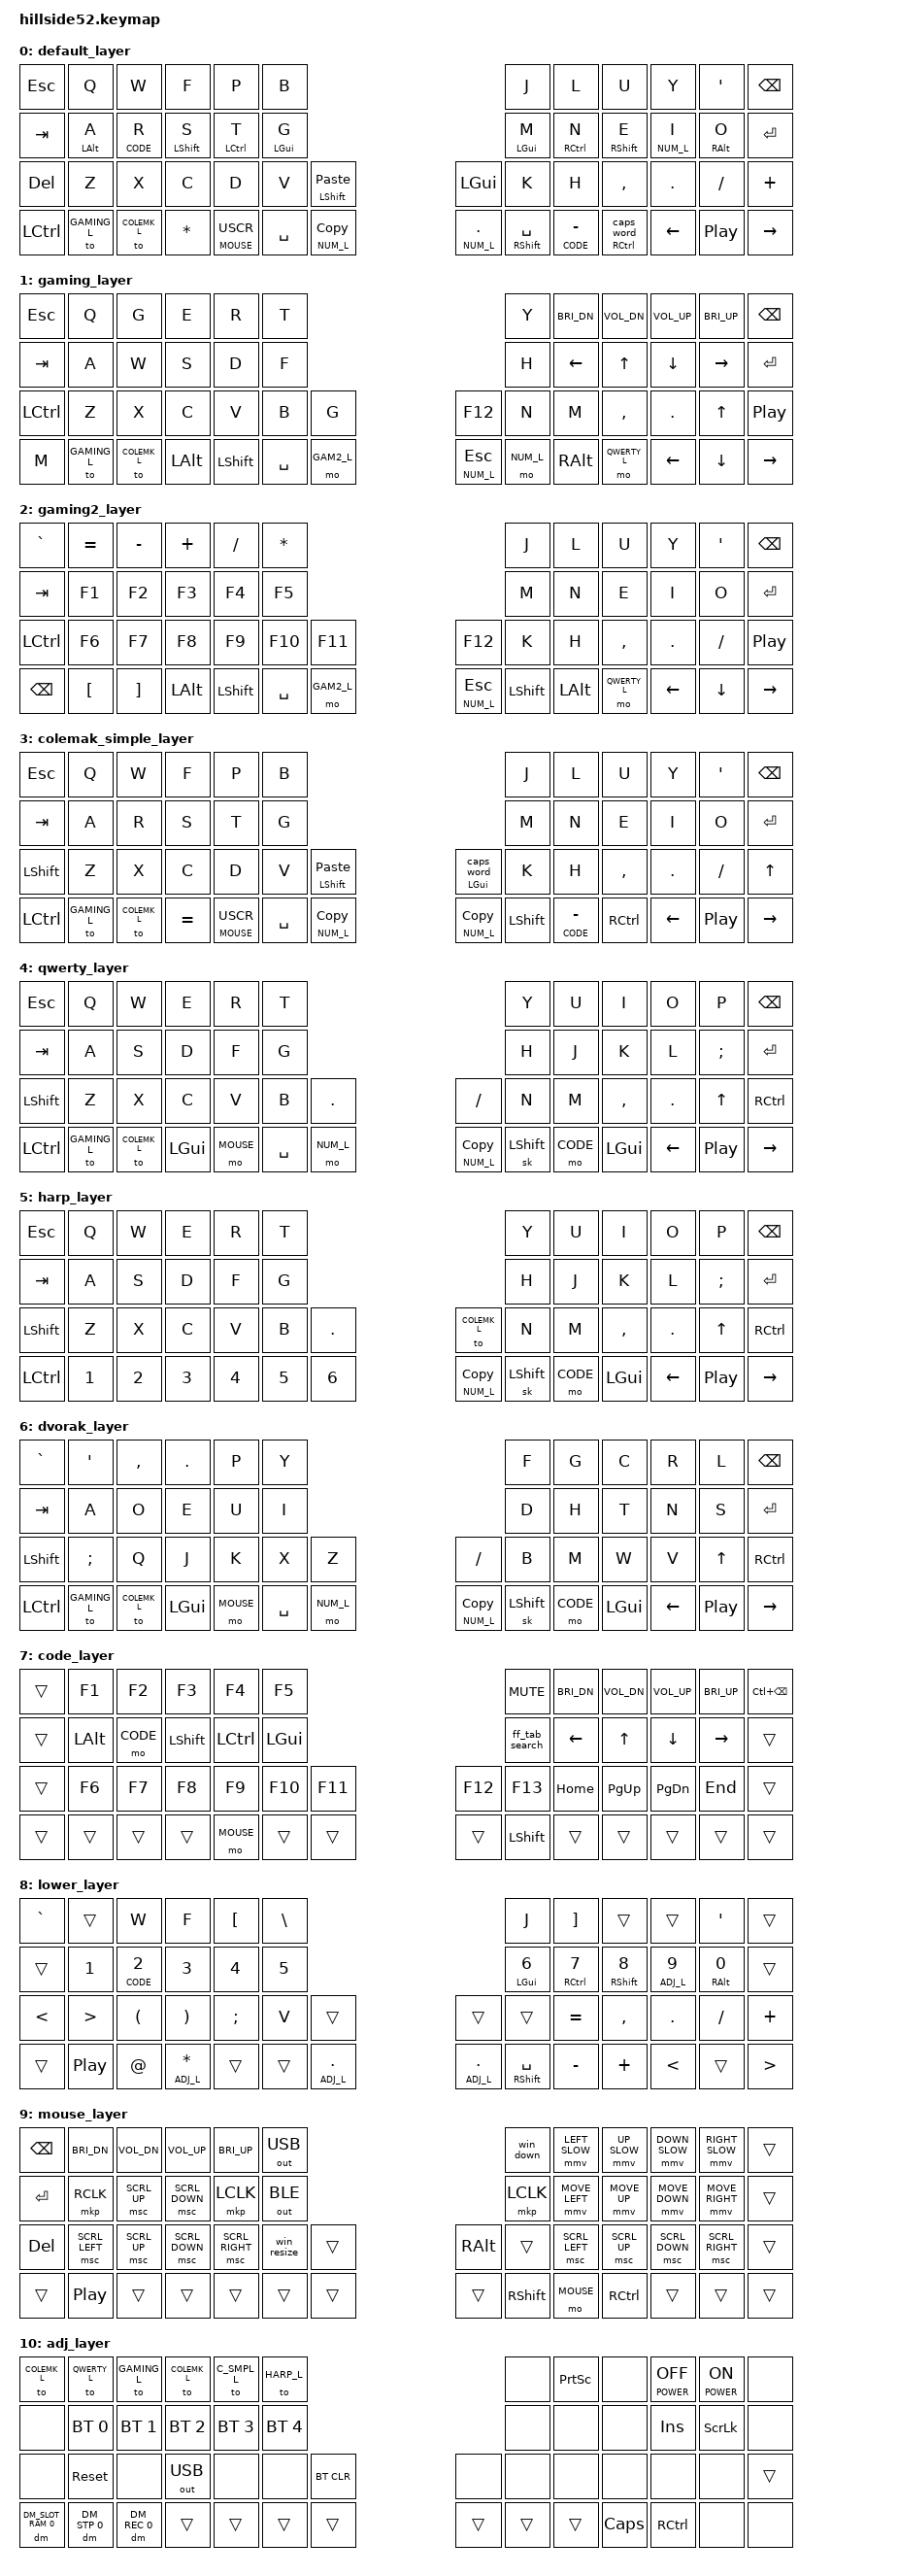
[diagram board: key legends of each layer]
/*
 * Copyright (c) 2021-2022 The ZMK Contributors
 *
 * SPDX-License-Identifier: MIT
 */

#include <behaviors.dtsi>
#include <dt-bindings/zmk/bt.h>
#include <dt-bindings/zmk/ext_power.h>
#include <dt-bindings/zmk/keys.h>
#include <dt-bindings/zmk/outputs.h>

#include <dt-bindings/zmk/mouse.h>
#include <behaviors/mouse_keys.dtsi>

#include <dt-bindings/zmk/kscan_mock.h>

#include <dt-bindings/zmk/dynamic_macros.h>
#include <behaviors/dynamic_macro.dtsi>

#define USCR UNDERSCORE
#define POWER ext_power
 
#define COLEMK_L 0
#define GAMING_L 1
#define GAM2_L   2
#define C_SMPL_L 3
#define QWERTY_L 4
#define HARP_L   5
#define DVORAK_L 6
#define CODE     7
#define NUM_L    8
#define MOUSE    9
#define ADJ_L    10

#define Undo   LC(Z)
#define Cut    LC(X)
#define Copy   LC(C)
#define Paste  LC(V)
#define Redo   LC(Y)

#define U_MOUSE_MOVE_MAX 1600                     /* <--- New max speed setting (default: 600) */
#undef MOVE_UP
#undef MOVE_DOWN
#undef MOVE_LEFT
#undef MOVE_RIGHT
#define MOVE_UP MOVE_Y(-U_MOUSE_MOVE_MAX)
#define MOVE_DOWN MOVE_Y(U_MOUSE_MOVE_MAX)
#define MOVE_LEFT MOVE_X(-U_MOUSE_MOVE_MAX)
#define MOVE_RIGHT MOVE_X(U_MOUSE_MOVE_MAX)


#define U_MOUSE_MOVE_SLOW_MAX 500                     /* <--- New max speed setting (default: 600) */
#define UP_SLOW MOVE_Y(-U_MOUSE_MOVE_SLOW_MAX)
#define DOWN_SLOW MOVE_Y(U_MOUSE_MOVE_SLOW_MAX)
#define LEFT_SLOW MOVE_X(-U_MOUSE_MOVE_SLOW_MAX)
#define RIGHT_SLOW MOVE_X(U_MOUSE_MOVE_SLOW_MAX)

#define U_MOUSE_SCRL_MAX 15                    /* <--- New max speed setting (default: 10) */
#undef SCRL_UP
#undef SCRL_DOWN
#undef SCRL_LEFT
#undef SCRL_RIGHT
#define SCRL_UP MOVE_Y(U_MOUSE_SCRL_MAX)
#define SCRL_DOWN MOVE_Y(-U_MOUSE_SCRL_MAX)
#define SCRL_LEFT MOVE_X(-U_MOUSE_SCRL_MAX)
#define SCRL_RIGHT MOVE_X(U_MOUSE_SCRL_MAX)

&msc {
  time-to-max-speed-ms = <1>;                 /* <--- How long time until max speed is reached (default: 300) */
};

&caps_word {
        continue-list = <USCR MINUS BSPC LS(BSPC)>;
};
&mmv {
	time-to-max-speed-ms = <300>;             /* <--- How long time until max speed is reached (default: 300) */
};

/ {
	macros {
		ff_tab_search: ff_tab_search {
		    compatible = "zmk,behavior-macro";
		    #binding-cells = <0>;
		    bindings
			= <&macro_press &kp LCTRL>
			, <&macro_tap &kp T>
			, <&macro_release &kp LCTRL>
			, <&macro_tap &kp PERCENT &kp SPACE>
			;
		};
		win_up: win_up {
		    compatible = "zmk,behavior-macro";
		    #binding-cells = <0>;
		    bindings
			= <&macro_press &kp LGUI>
			, <&macro_tap &kp UP>
			, <&macro_release &kp LGUI>
			;
		};
		win_down: win_down {
		    compatible = "zmk,behavior-macro";
		    #binding-cells = <0>;
		    bindings
			= <&macro_press &kp LGUI>
			, <&macro_tap &kp DOWN>
			, <&macro_release &kp LGUI>
			;
		};
		win_resize: win_resize {
		    compatible = "zmk,behavior-macro";
		    #binding-cells = <0>;
		    bindings
			= <&macro_tap &mkp RCLK>
			, <&macro_tap &kp ESC>

			, <&macro_press &kp LALT>
			, <&macro_tap &kp SPACE>
			, <&macro_release &kp LALT>
			, <&macro_tap &kp S &kp UP &kp LEFT>

    			, <&macro_pause_for_release>
			, <&macro_tap &mkp LCLK>
			;
		};
		win_move: win_move {
		    compatible = "zmk,behavior-macro";
		    #binding-cells = <0>;
		    bindings
			= <&macro_tap &mkp RCLK>
			, <&macro_tap &kp ESC>

			, <&macro_press &kp LALT>
			, <&macro_tap &kp SPACE>
			, <&macro_release &kp LALT>
			, <&macro_tap &kp M &kp DOWN>

			, <&macro_pause_for_release>
			, <&macro_tap &mkp LCLK>
			;
		};
	};
        behaviors {
        hlf: homerow_layer_fast {
            compatible = "zmk,behavior-hold-tap";
            #binding-cells = <2>;
            tapping-term-ms = <190>;
            require-prior-idle-ms = <0>;
            quick-tap-ms = <0>;
            flavor = "balanced";
            bindings = <&mo>, <&kp>;
            };
        hl: homerow_layer {
            compatible = "zmk,behavior-hold-tap";
            #binding-cells = <2>;
            tapping-term-ms = <400>;
            require-prior-idle-ms = <0>;
            quick-tap-ms = <0>;
            flavor = "balanced";
            bindings = <&mo>, <&kp>;
            };
        hm: homerow_mods {
            compatible = "zmk,behavior-hold-tap";
            #binding-cells = <2>;
            tapping-term-ms = <400>;
            require-prior-idle-ms = <0>;
            quick-tap-ms = <0>;
            flavor = "balanced";
            bindings = <&kp>, <&kp>;
            };
        mpcaps: mod_preferred_caps_word {
            compatible = "zmk,behavior-hold-tap";
            #binding-cells = <2>;
            tapping-term-ms = <300>;
            quick-tap-ms = <0>;
            flavor = "hold-preferred";
            bindings = <&kp>, <&caps_word>;
            };
        mp: mod_preferred {
            compatible = "zmk,behavior-hold-tap";
            #binding-cells = <2>;
            tapping-term-ms = <300>;
            quick-tap-ms = <0>;
            flavor = "hold-preferred";
            bindings = <&kp>, <&kp>;
            };
        mlt: my_layer_tap {
            compatible = "zmk,behavior-hold-tap";
            #binding-cells = <2>;
            tapping-term-ms = <300>;
            quick-tap-ms = <0>;
            flavor = "hold-preferred";
            bindings = <&mo>, <&kp>;
            };
        };

        keymap {
                compatible = "zmk,keymap";

                default_layer {
/* COLEMAK-DH
 */
                        bindings = <
//──────────────┬───────────────┬───────────────┬───────────────┬───────────────┬───────────────┐                                                               ┌───────────────┬───────────────┬───────────────┬───────────────┬───────────────┬───────────────┐
&kp ESC         &kp Q           &kp W           &kp F           &kp P           &kp B                                                                           &kp J           &kp L           &kp U           &kp Y           &kp SQT         &kp BSPC
//──────────────┼───────────────┼───────────────┼───────────────┼───────────────┼───────────────┤                                                               ├───────────────┼───────────────┼───────────────┼───────────────┼───────────────┼───────────────┤
&kp TAB         &hm LALT A      &hl CODE R      &hm LSHIFT S    &hm LCTRL T     &hm LGUI G                                                                      &hm LGUI M      &hm RCTRL N     &hm RSHIFT E    &hlf NUM_L I    &hm RALT O      &kp ENTER
//──────────────┼───────────────┼───────────────┼───────────────┼───────────────┼───────────────┤                                                               ├───────────────┼───────────────┼───────────────┼───────────────┼───────────────┼───────────────┤
&kp DEL         &kp Z           &kp X           &kp C           &kp D           &kp V           &hm LSHIFT Paste                                &kp LGUI        &kp K           &kp H           &kp COMMA       &kp DOT         &kp SLASH       &kp PLUS
//──────────────┼───────────────┼───────────────┼───────────────┼───────────────┼───────────────┼───────────────┼───────────────┼───────────────┼───────────────┼───────────────┼───────────────┼───────────────┼───────────────┼───────────────┼───────────────┤
&kp LCTRL       &to GAMING_L    &to COLEMK_L                    &kp ASTRK       &mlt MOUSE USCR &kp SPACE       &hl NUM_L Copy  &hl NUM_L DOT   &mp RSHIFT SPACE&hl CODE MINUS  &mpcaps RCTRL 0                 &kp LEFT        &kp C_PLAY_PAUSE&kp RIGHT
//──────────────┴───────────────┴───────────────┴───────────────┴───────────────┴───────────────┴───────────────┴───────────────┴───────────────┴───────────────┴───────────────┴───────────────┴───────────────┴───────────────┴───────────────┴───────────────┘
    >;

                        sensor-bindings = <&inc_dec_kp C_VOL_UP C_VOL_DN &inc_dec_kp PG_UP PG_DN>;
                };

                gaming_layer {
/* GAMING_L
 */
                        bindings = <
//──────────────┬───────────────┬───────────────┬───────────────┬───────────────┬───────────────┐                                                               ┌───────────────┬───────────────┬───────────────┬───────────────┬───────────────┬───────────────┐
&kp ESC         &kp Q           &kp G           &kp E           &kp R           &kp T                                                                           &kp Y           &kp C_BRI_DN    &kp C_VOL_DN    &kp C_VOL_UP    &kp C_BRI_UP    &kp BSPC
//──────────────┼───────────────┼───────────────┼───────────────┼───────────────┼───────────────┤                                                               ├───────────────┼───────────────┼───────────────┼───────────────┼───────────────┼───────────────┤
&kp TAB         &kp A           &kp W           &kp S           &kp D           &kp F                                                                           &kp H           &kp LEFT        &kp UP          &kp DOWN        &kp RIGHT       &kp ENTER
//──────────────┼───────────────┼───────────────┼───────────────┼───────────────┼───────────────┤                                                               ├───────────────┼───────────────┼───────────────┼───────────────┼───────────────┼───────────────┤
&kp LCTRL       &kp Z           &kp X           &kp C           &kp V           &kp B           &kp G                                           &kp F12         &kp N           &kp M           &kp COMMA       &kp DOT         &kp UP          &kp C_PLAY_PAUSE
//──────────────┼───────────────┼───────────────┼───────────────┼───────────────┼───────────────┼───────────────┼───────────────┼───────────────┼───────────────┼───────────────┼───────────────┼───────────────┼───────────────┼───────────────┼───────────────┤
&kp M           &to GAMING_L    &to COLEMK_L                    &kp LALT        &kp LSHIFT      &kp SPACE       &mo GAM2_L      &hl NUM_L ESC   &mo NUM_L       &kp RALT        &mo QWERTY_L                    &kp LEFT        &kp DOWN        &kp RIGHT
//──────────────┴───────────────┴───────────────┴───────────────┴───────────────┴───────────────┴───────────────┴───────────────┴───────────────┴───────────────┴───────────────┴───────────────┴───────────────┴───────────────┴───────────────┴───────────────┘
    >;

                        sensor-bindings = <&inc_dec_kp C_VOL_UP C_VOL_DN &inc_dec_kp PG_UP PG_DN>;
                };
                gaming2_layer {
/* GAM2_L
 */
                        bindings = <
//──────────────┬───────────────┬───────────────┬───────────────┬───────────────┬───────────────┐                                                               ┌───────────────┬───────────────┬───────────────┬───────────────┬───────────────┬───────────────┐
&kp GRAVE       &kp EQUAL       &kp MINUS       &kp PLUS        &kp SLASH       &kp ASTRK                                                                       &kp J           &kp L           &kp U           &kp Y           &kp SQT         &kp BSPC
//──────────────┼───────────────┼───────────────┼───────────────┼───────────────┼───────────────┤                                                               ├───────────────┼───────────────┼───────────────┼───────────────┼───────────────┼───────────────┤
&kp TAB         &kp F1          &kp F2          &kp F3          &kp F4          &kp F5                                                                          &kp M           &kp N           &kp E           &kp I           &kp O           &kp ENTER
//──────────────┼───────────────┼───────────────┼───────────────┼───────────────┼───────────────┤                                                               ├───────────────┼───────────────┼───────────────┼───────────────┼───────────────┼───────────────┤
&kp LCTRL       &kp F6          &kp F7          &kp F8          &kp F9          &kp F10         &kp F11                                         &kp F12         &kp K           &kp H           &kp COMMA       &kp DOT         &kp SLASH       &kp C_PLAY_PAUSE
//──────────────┼───────────────┼───────────────┼───────────────┼───────────────┼───────────────┼───────────────┼───────────────┼───────────────┼───────────────┼───────────────┼───────────────┼───────────────┼───────────────┼───────────────┼───────────────┤
&kp BSPC        &kp LBKT        &kp RBKT                        &kp LALT        &kp LSHIFT      &kp SPACE       &mo GAM2_L      &hl NUM_L ESC   &kp LSHIFT      &kp LALT        &mo QWERTY_L                    &kp LEFT        &kp DOWN        &kp RIGHT
//──────────────┴───────────────┴───────────────┴───────────────┴───────────────┴───────────────┴───────────────┴───────────────┴───────────────┴───────────────┴───────────────┴───────────────┴───────────────┴───────────────┴───────────────┴───────────────┘
    >;

                        sensor-bindings = <&inc_dec_kp C_VOL_UP C_VOL_DN &inc_dec_kp PG_UP PG_DN>;
                };

                colemak_simple_layer {
/* C_SMPL_L (no home row mods an fewer multi-purpose keys. useful for some games)
 */
                        bindings = <
//──────────────┬───────────────┬───────────────┬───────────────┬───────────────┬───────────────┐                                                               ┌───────────────┬───────────────┬───────────────┬───────────────┬───────────────┬───────────────┐
&kp ESC         &kp Q           &kp W           &kp F           &kp P           &kp B                                                                           &kp J           &kp L           &kp U           &kp Y           &kp SQT         &kp BSPC
//──────────────┼───────────────┼───────────────┼───────────────┼───────────────┼───────────────┤                                                               ├───────────────┼───────────────┼───────────────┼───────────────┼───────────────┼───────────────┤
&kp TAB         &kp A           &kp R           &kp S           &kp T           &kp G                                                                           &kp M           &kp N           &kp E           &kp I           &kp O           &kp ENTER
//──────────────┼───────────────┼───────────────┼───────────────┼───────────────┼───────────────┤                                                               ├───────────────┼───────────────┼───────────────┼───────────────┼───────────────┼───────────────┤
&kp LSHFT       &kp Z           &kp X           &kp C           &kp D           &kp V           &hm LSHIFT Paste                                &mpcaps LGUI 0  &kp K           &kp H           &kp COMMA       &kp DOT         &kp SLASH       &kp UP
//──────────────┼───────────────┼───────────────┼───────────────┼───────────────┼───────────────┼───────────────┼───────────────┼───────────────┼───────────────┼───────────────┼───────────────┼───────────────┼───────────────┼───────────────┼───────────────┤
&kp LCTRL       &to GAMING_L    &to COLEMK_L                    &kp EQUAL       &mlt MOUSE USCR &kp SPACE       &hl NUM_L Copy  &hl NUM_L Copy  &kp LSHIFT      &hl CODE MINUS  &kp RCTRL                       &kp LEFT        &kp C_PLAY_PAUSE&kp RIGHT
//──────────────┴───────────────┴───────────────┴───────────────┴───────────────┴───────────────┴───────────────┴───────────────┴───────────────┴───────────────┴───────────────┴───────────────┴───────────────┴───────────────┴───────────────┴───────────────┘
    >;

                        sensor-bindings = <&inc_dec_kp C_VOL_UP C_VOL_DN &inc_dec_kp PG_UP PG_DN>;
                };

                qwerty_layer {
/* QWERTY
 */
                        bindings = <
//──────────────┬───────────────┬───────────────┬───────────────┬───────────────┬───────────────┐                                                               ┌───────────────┬───────────────┬───────────────┬───────────────┬───────────────┬───────────────┐
&kp ESC         &kp Q           &kp W           &kp E           &kp R           &kp T                                                                           &kp Y           &kp U           &kp I           &kp O           &kp P           &kp BSPC
//──────────────┼───────────────┼───────────────┼───────────────┼───────────────┼───────────────┤                                                               ├───────────────┼───────────────┼───────────────┼───────────────┼───────────────┼───────────────┤
&kp TAB         &kp A           &kp S           &kp D           &kp F           &kp G                                                                           &kp H           &kp J           &kp K           &kp L           &kp SEMI        &kp ENTER
//──────────────┼───────────────┼───────────────┼───────────────┼───────────────┼───────────────┤                                                               ├───────────────┼───────────────┼───────────────┼───────────────┼───────────────┼───────────────┤
&kp LSHFT       &kp Z           &kp X           &kp C           &kp V           &kp B           &kp DOT                                         &kp SLASH       &kp N           &kp M           &kp COMMA       &kp DOT         &kp UP          &kp RCTRL
//──────────────┼───────────────┼───────────────┼───────────────┼───────────────┼───────────────┼───────────────┼───────────────┼───────────────┼───────────────┼───────────────┼───────────────┼───────────────┼───────────────┼───────────────┼───────────────┤
&kp LCTRL       &to GAMING_L    &to COLEMK_L                    &kp LGUI        &mo MOUSE       &kp SPACE       &mo NUM_L       &lt NUM_L Copy  &sk LSHIFT      &mo CODE        &kp LGUI                        &kp LEFT        &kp C_PLAY_PAUSE&kp RIGHT
//──────────────┴───────────────┴───────────────┴───────────────┴───────────────┴───────────────┴───────────────┴───────────────┴───────────────┴───────────────┴───────────────┴───────────────┴───────────────┴───────────────┴───────────────┴───────────────┘
    >;

                        sensor-bindings = <&inc_dec_kp C_VOL_UP C_VOL_DN &inc_dec_kp PG_UP PG_DN>;
                };

                harp_layer {
/* HARP_L: RUST HARP INPUTS
 */
                        bindings = <
//──────────────┬───────────────┬───────────────┬───────────────┬───────────────┬───────────────┐                                                               ┌───────────────┬───────────────┬───────────────┬───────────────┬───────────────┬───────────────┐
&kp ESC         &kp Q           &kp W           &kp E           &kp R           &kp T                                                                           &kp Y           &kp U           &kp I           &kp O           &kp P           &kp BSPC
//──────────────┼───────────────┼───────────────┼───────────────┼───────────────┼───────────────┤                                                               ├───────────────┼───────────────┼───────────────┼───────────────┼───────────────┼───────────────┤
&kp TAB         &kp A           &kp S           &kp D           &kp F           &kp G                                                                           &kp H           &kp J           &kp K           &kp L           &kp SEMI        &kp ENTER
//──────────────┼───────────────┼───────────────┼───────────────┼───────────────┼───────────────┤                                                               ├───────────────┼───────────────┼───────────────┼───────────────┼───────────────┼───────────────┤
&kp LSHFT       &kp Z           &kp X           &kp C           &kp V           &kp B           &kp DOT                                         &to COLEMK_L    &kp N           &kp M           &kp COMMA       &kp DOT         &kp UP          &kp RCTRL
//──────────────┼───────────────┼───────────────┼───────────────┼───────────────┼───────────────┼───────────────┼───────────────┼───────────────┼───────────────┼───────────────┼───────────────┼───────────────┼───────────────┼───────────────┼───────────────┤
&kp LCTRL       &kp N1          &kp N2                          &kp N3          &kp N4          &kp N5          &kp N6          &lt NUM_L Copy  &sk LSHIFT      &mo CODE        &kp LGUI                        &kp LEFT        &kp C_PLAY_PAUSE&kp RIGHT
//──────────────┴───────────────┴───────────────┴───────────────┴───────────────┴───────────────┴───────────────┴───────────────┴───────────────┴───────────────┴───────────────┴───────────────┴───────────────┴───────────────┴───────────────┴───────────────┘
    >;

                        sensor-bindings = <&inc_dec_kp C_VOL_UP C_VOL_DN &inc_dec_kp PG_UP PG_DN>;
                };

                dvorak_layer {
/* DVORAK
 */
                        bindings = <
//──────────────┬───────────────┬───────────────┬───────────────┬───────────────┬───────────────┐                                                               ┌───────────────┬───────────────┬───────────────┬───────────────┬───────────────┬───────────────┐
&kp GRAVE       &kp SQT         &kp COMMA       &kp DOT         &kp P           &kp Y                                                                           &kp F           &kp G           &kp C           &kp R           &kp L           &kp BSPC
//──────────────┼───────────────┼───────────────┼───────────────┼───────────────┼───────────────┤                                                               ├───────────────┼───────────────┼───────────────┼───────────────┼───────────────┼───────────────┤
&kp TAB         &kp A           &kp O           &kp E           &kp U           &kp I                                                                           &kp D           &kp H           &kp T           &kp N           &kp S           &kp ENTER
//──────────────┼───────────────┼───────────────┼───────────────┼───────────────┼───────────────┤                                                               ├───────────────┼───────────────┼───────────────┼───────────────┼───────────────┼───────────────┤
&kp LSHFT       &kp SEMI        &kp Q           &kp J           &kp K           &kp X           &kp Z                                           &kp SLASH       &kp B           &kp M           &kp W           &kp V           &kp UP          &kp RCTRL
//──────────────┼───────────────┼───────────────┼───────────────┼───────────────┼───────────────┼───────────────┼───────────────┼───────────────┼───────────────┼───────────────┼───────────────┼───────────────┼───────────────┼───────────────┼───────────────┤
&kp LCTRL       &to GAMING_L    &to COLEMK_L                    &kp LGUI        &mo MOUSE       &kp SPACE       &mo NUM_L       &lt NUM_L Copy  &sk LSHIFT      &mo CODE        &kp LGUI                        &kp LEFT        &kp C_PLAY_PAUSE&kp RIGHT
//──────────────┴───────────────┴───────────────┴───────────────┴───────────────┴───────────────┴───────────────┴───────────────┴───────────────┴───────────────┴───────────────┴───────────────┴───────────────┴───────────────┴───────────────┴───────────────┘
    >;

                        sensor-bindings = <&inc_dec_kp C_VOL_UP C_VOL_DN &inc_dec_kp PG_UP PG_DN>;
                };

                code_layer {
/* CODE
 */
                        bindings = <
//──────────────┬───────────────┬───────────────┬───────────────┬───────────────┬───────────────┐                                                               ┌───────────────┬───────────────┬───────────────┬───────────────┬───────────────┬───────────────┐
&trans          &kp F1          &kp F2          &kp F3          &kp F4          &kp F5                                                                          &kp C_MUTE      &kp C_BRI_DN    &kp C_VOL_DN    &kp C_VOL_UP    &kp C_BRI_UP    &kp LC(BSPC)
//──────────────┼───────────────┼───────────────┼───────────────┼───────────────┼───────────────┤                                                               ├───────────────┼───────────────┼───────────────┼───────────────┼───────────────┼───────────────┤
&trans          &kp LALT        &mo CODE        &kp LSHIFT      &kp LCTRL       &kp LGUI                                                                        &ff_tab_search  &kp LEFT        &kp UP          &kp DOWN        &kp RIGHT       &trans
//──────────────┼───────────────┼───────────────┼───────────────┼───────────────┼───────────────┤                                                               ├───────────────┼───────────────┼───────────────┼───────────────┼───────────────┼───────────────┤
&trans          &kp F6          &kp F7          &kp F8          &kp F9          &kp F10         &kp F11                                         &kp F12         &kp F13         &kp HOME        &kp PG_UP       &kp PG_DN       &kp END         &trans
//──────────────┼───────────────┼───────────────┼───────────────┼───────────────┼───────────────┼───────────────┼───────────────┼───────────────┼───────────────┼───────────────┼───────────────┼───────────────┼───────────────┼───────────────┼───────────────┤
&trans          &trans          &trans                          &trans          &mo MOUSE       &trans          &trans          &trans          &kp LSHIFT      &trans          &trans                          &trans          &trans          &trans
//──────────────┴───────────────┴───────────────┴───────────────┴───────────────┴───────────────┴───────────────┴───────────────┴───────────────┴───────────────┴───────────────┴───────────────┴───────────────┴───────────────┴───────────────┴───────────────┘
    >;

                        sensor-bindings = <&inc_dec_kp PG_UP PG_DN &inc_dec_kp C_VOL_UP C_VOL_DN>;
                };

                lower_layer {
/* NUM_L
 */
                        bindings = <
//──────────────┬───────────────┬───────────────┬───────────────┬───────────────┬───────────────┐                                                               ┌───────────────┬───────────────┬───────────────┬───────────────┬───────────────┬───────────────┐
&kp GRAVE       &trans          &kp W           &kp F           &kp LBKT        &kp BSLH                                                                        &kp J           &kp RBKT        &trans          &trans          &kp SQT         &trans
//──────────────┼───────────────┼───────────────┼───────────────┼───────────────┼───────────────┤                                                               ├───────────────┼───────────────┼───────────────┼───────────────┼───────────────┼───────────────┤
&trans          &kp N1          &hl CODE N2     &kp N3          &kp N4          &kp N5                                                                          &hm LGUI N6     &hm RCTRL N7    &hm RSHIFT N8   &hlf ADJ_L N9   &hm RALT N0     &trans
//──────────────┼───────────────┼───────────────┼───────────────┼───────────────┼───────────────┤                                                               ├───────────────┼───────────────┼───────────────┼───────────────┼───────────────┼───────────────┤
&kp LT          &kp GT          &kp LPAR        &kp RPAR        &kp SEMI        &kp V           &trans                                          &trans          &trans          &kp EQUAL       &kp COMMA       &kp DOT         &kp SLASH       &kp PLUS
//──────────────┼───────────────┼───────────────┼───────────────┼───────────────┼───────────────┼───────────────┼───────────────┼───────────────┼───────────────┼───────────────┼───────────────┼───────────────┼───────────────┼───────────────┼───────────────┤
&trans          &kp C_PLAY_PAUSE&kp AT                          &hl ADJ_L ASTRK &trans          &trans          &hl ADJ_L DOT  &hl ADJ_L DOT   &mp RSHIFT SPACE&kp MINUS       &kp PLUS                        &kp LT          &trans          &kp GT
//──────────────┴───────────────┴───────────────┴───────────────┴───────────────┴───────────────┴───────────────┴───────────────┴───────────────┴───────────────┴───────────────┴───────────────┴───────────────┴───────────────┴───────────────┴───────────────┘
    >;

                        sensor-bindings = <&inc_dec_kp PG_UP PG_DN &inc_dec_kp C_VOL_UP C_VOL_DN>;
                };

                mouse_layer {
/* MOUSE
 */
                        bindings = <
//──────────────┬───────────────┬───────────────┬───────────────┬───────────────┬───────────────┐                                                               ┌───────────────┬───────────────┬───────────────┬───────────────┬───────────────┬───────────────┐
&kp BSPC        &kp C_BRI_DN    &kp C_VOL_DN    &kp C_VOL_UP    &kp C_BRI_UP    &out OUT_USB                                                                    &win_down       &mmv LEFT_SLOW  &mmv UP_SLOW    &mmv DOWN_SLOW  &mmv RIGHT_SLOW &trans
//──────────────┼───────────────┼───────────────┼───────────────┼───────────────┼───────────────┤                                                               ├───────────────┼───────────────┼───────────────┼───────────────┼───────────────┼───────────────┤
&kp ENTER       &mkp RCLK       &msc SCRL_UP    &msc SCRL_DOWN  &mkp LCLK       &out OUT_BLE                                                                    &mkp LCLK       &mmv MOVE_LEFT  &mmv MOVE_UP    &mmv MOVE_DOWN  &mmv MOVE_RIGHT &trans
//──────────────┼───────────────┼───────────────┼───────────────┼───────────────┼───────────────┤                                                               ├───────────────┼───────────────┼───────────────┼───────────────┼───────────────┼───────────────┤
&kp DEL         &msc SCRL_LEFT  &msc SCRL_UP    &msc SCRL_DOWN  &msc SCRL_RIGHT &win_resize     &trans                                          &kp RALT        &trans          &msc SCRL_LEFT  &msc SCRL_UP    &msc SCRL_DOWN  &msc SCRL_RIGHT &trans
//──────────────┼───────────────┼───────────────┼───────────────┼───────────────┼───────────────┼───────────────┼───────────────┼───────────────┼───────────────┼───────────────┼───────────────┼───────────────┼───────────────┼───────────────┼───────────────┤
&trans          &kp C_PLAY_PAUSE&trans                          &trans          &trans          &trans          &trans          &trans          &kp RSHIFT      &mo MOUSE       &kp RCTRL                       &trans          &trans          &trans
//──────────────┴───────────────┴───────────────┴───────────────┴───────────────┴───────────────┴───────────────┴───────────────┴───────────────┴───────────────┴───────────────┴───────────────┴───────────────┴───────────────┴───────────────┴───────────────┘
    >;

                        sensor-bindings = <&inc_dec_kp C_VOL_UP C_VOL_DN &inc_dec_kp PG_UP PG_DN>;
                };

                adj_layer {
/* ADJUST
 */
                        bindings = <
//──────────────┬───────────────┬───────────────┬───────────────┬───────────────┬───────────────┐                                                               ┌───────────────┬───────────────┬───────────────┬───────────────┬───────────────┬───────────────┐
&to COLEMK_L    &to QWERTY_L    &to GAMING_L    &to COLEMK_L    &to C_SMPL_L    &to HARP_L                                                                      &none           &kp PRINTSCREEN &none           &POWER EP_OFF   &POWER EP_ON    &none
//──────────────┼───────────────┼───────────────┼───────────────┼───────────────┼───────────────┤                                                               ├───────────────┼───────────────┼───────────────┼───────────────┼───────────────┼───────────────┤
&none           &bt BT_SEL 0    &bt BT_SEL 1    &bt BT_SEL 2    &bt BT_SEL 3    &bt BT_SEL 4                                                                    &none           &none           &none           &kp INSERT      &kp SCROLLLOCK  &none
//──────────────┼───────────────┼───────────────┼───────────────┼───────────────┼───────────────┤                                                               ├───────────────┼───────────────┼───────────────┼───────────────┼───────────────┼───────────────┤
&none           &sys_reset      &none           &out OUT_USB    &none           &none           &bt BT_CLR                                      &none           &none           &none           &none           &none           &none           &trans
//──────────────┼───────────────┼───────────────┼───────────────┼───────────────┼───────────────┼───────────────┼───────────────┼───────────────┼───────────────┼───────────────┼───────────────┼───────────────┼───────────────┼───────────────┼───────────────┤
&dm DM_SLOT_RAM 0               &dm DM_STP 0    &dm DM_REC 0    &trans          &trans          &trans          &trans          &trans          &trans          &trans          &kp CAPSLOCK                    &kp RCTRL       &none           &none
//──────────────┴───────────────┴───────────────┴───────────────┴───────────────┴───────────────┴───────────────┴───────────────┴───────────────┴───────────────┴───────────────┴───────────────┴───────────────┴───────────────┴───────────────┴───────────────┘
    >;

                        sensor-bindings = <&inc_dec_kp C_VOL_UP C_VOL_DN &inc_dec_kp PG_UP PG_DN>;
                };
        };
};


